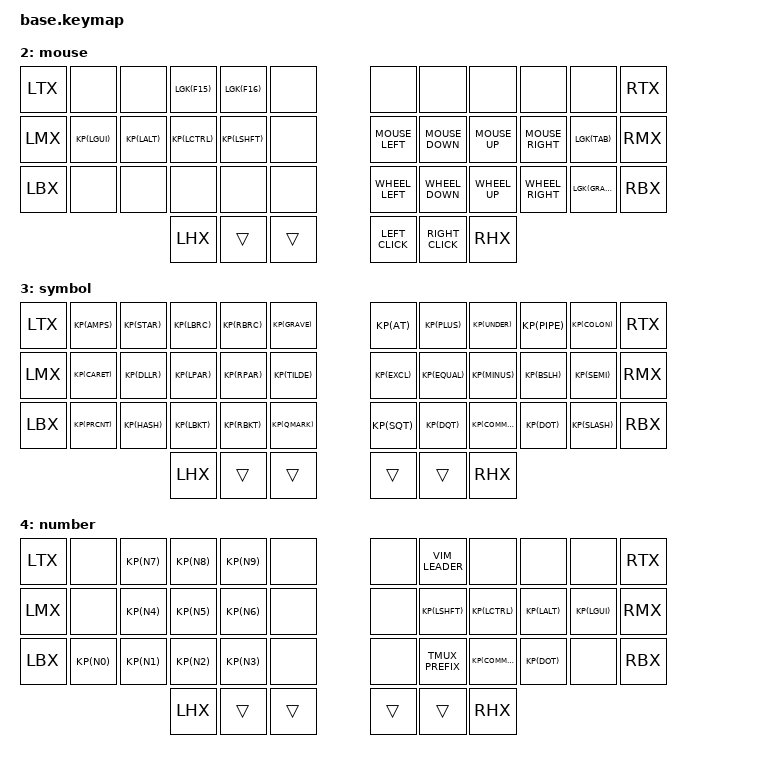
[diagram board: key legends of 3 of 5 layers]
/*
 * Copyright (c) 2020 The ZMK Contributors
 *
 * SPDX-License-Identifier: MIT
 */

// Layers
#define BASE 0
#define NAV 1
#define MOU 2
#define SYM 3
#define NUM 4

// Keys
#define KEYS_L LT0 LT1 LT2 LT3 LT4 LM0 LM1 LM2 LM3 LM4 LB0 LB1 LB2 LB3 LB4
#define KEYS_R RT0 RT1 RT2 RT3 RT4 RM0 RM1 RM2 RM3 RM4 RB0 RB1 RB2 RB3 RB4
#define THUMBS LH1 LH0 RH0 RH1

// Keymaps
#define XXX &none
#define ___ &trans
#define KP(k) &kp k
#define LGK(k) &kp LG(k)
#define LSK(k) &kp LS(k)
#define LCK(k) &kp LC(k)
#define HYPER(k) &kp LC(LS(LA(LG(k))))

#define NAV_ESC &lt NAV ESC
#define MOU_SPACE &lt MOU SPACE
#define NUM_ENTER &lt NUM ENTER
#define SYM_BSPC &lt SYM BSPC

#define BRI_DOWN &kp C_BRI_DN
#define BRI_UP &kp C_BRI_UP

#define VOL_UP &kp C_VOL_UP
#define VOL_DOWN &kp C_VOL_DN
#define VOL_MUTE &kp C_MUTE

#define TMUX_PREFIX LCK(F)
#define VIM_LEADER KP(SEMI)

#include <behaviors.dtsi>
#include <dt-bindings/zmk/bt.h>
#include <dt-bindings/zmk/keys.h>

#include "zmk-helpers/helper.h"

#include "includes/mouse.dtsi"
#include "includes/macros.dtsi"
#include "includes/combos.dtsi"
#include "includes/mods.dtsi"
#include "includes/swapper.dtsi"
#include "includes/settings.dtsi"

ZMK_LAYER(base,
  //╭──────────┬──────────┬──────────┬──────────┬──────────┬──────────╮   ╭──────────┬──────────┬──────────┬──────────┬──────────┬──────────╮
  //│          │  Q       │  W       │  E       │  R       │  T       │   │  Y       │  U       │  I       │  O       │  P       │          │
      _LTX       KP(Q)      KP(W)      KP(E)      KP(R)      KP(T)          KP(Y)      KP(U)      KP(I)      KP(O)      KP(P)      _RTX
  //├──────────┼──────────┼──────────┼──────────┼──────────┼──────────┤   ├──────────┼──────────┼──────────┼──────────┼──────────┼──────────┤
  //│          │  A       │  S       │  D       │  F       │  G       │   │  H       │  J       │  K       │  L       │  ; :     │          │
      _LMX       HRML(A,         S,         D,         F,         G)        HRMR(H,         J,         K,         L,        SEMI)  _RMX
  //├──────────┼──────────┼──────────┼──────────┼──────────┼──────────┤   ├──────────┼──────────┼──────────┼──────────┼──────────┼──────────┤
  //│          │  Z       │  X       │  C       │  V       │  B       │   │  N       │  M       │  , <     │  . >     │  / ?     │          │
      _LBX       KP(Z)      KP(X)      KP(C)      KP(V)      KP(B)          KP(N)      KP(M)      KP(COMMA)  KP(DOT)    KP(SLASH)  _RBX
  //╰──────────┴──────────┴──────────┼──────────┼──────────┼──────────┤   ├──────────┼──────────┼──────────┼──────────┴──────────┴──────────╯
                                       _LHX       NAV_ESC    MOU_SPACE      NUM_ENTER  SYM_BSPC   _RHX
  //                                 ╰──────────┴──────────┴──────────╯   ╰──────────┴──────────┴──────────╯
)

ZMK_LAYER(navigation,
  //╭──────────┬──────────┬──────────┬──────────┬──────────┬──────────╮   ╭──────────┬──────────┬──────────┬──────────┬──────────┬──────────╮
  //│          │          │          │Screenshot│          │          │   │          │          │          │          │ CS + Tab │          │
      _LTX       BRI_DOWN   BRI_UP     HYPER(N4)  XXX        XXX            XXX        XXX        XXX        XXX       KP(LS(TAB)) _RTX
  //├──────────┼──────────┼──────────┼──────────┼──────────┼──────────┤   ├──────────┼──────────┼──────────┼──────────┼──────────┼──────────┤
  //│          │  Command │  Alt     │  Control │  Shift   │          │   │  Left    │  Down    │  Up      │  Right   │ Cmd + Tab│          │
      _LMX       KP(LGUI)   KP(LALT)   KP(LCTRL)  KP(LSHFT)  XXX            KP(LEFT)   KP(DOWN)   KP(UP)     KP(RIGHT)  &swapper   _RMX
  //├──────────┼──────────┼──────────┼──────────┼──────────┼──────────┤   ├──────────┼──────────┼──────────┼──────────┼──────────┼──────────┤
  //│          │ Vol down │ Vol up   │ Vol mute │Tmux Pre  │          │   │ Nav left │ Vim left │ Vim right│ Nav right│ Cmd + `  │          │
      _LBX       VOL_DOWN   VOL_UP     VOL_MUTE TMUX_PREFIX  XXX            KP(F23)    LSK(LEFT)  LSK(RIGHT) KP(F24)   LGK(GRAVE)  _RBX
  //╰──────────┴──────────┴──────────┼──────────┼──────────┼──────────┤   ├──────────┼──────────┼──────────┼──────────┴──────────┴──────────╯
                                       _LHX       ___        ___            ___        ___        _RHX
  //                                 ╰──────────┴──────────┴──────────╯   ╰──────────┴──────────┴──────────╯
)

ZMK_LAYER(mouse,
  //╭──────────┬──────────┬──────────┬──────────┬──────────┬──────────╮   ╭──────────┬──────────┬──────────┬──────────┬──────────┬──────────╮
  //│          │          │          │ Low speed│ Max speed│          │   │          │          │          │          │          │          │
      _LTX       XXX        XXX        LGK(F15)   LGK(F16)   XXX            XXX        XXX        XXX         XXX       XXX        _RTX
  //├──────────┼──────────┼──────────┼──────────┼──────────┼──────────┤   ├──────────┼──────────┼──────────┼──────────┼──────────┼──────────┤
  //│          │ Command  │ Alt      │ Control  │ Shift    │          │   │          │          │          │          │ Cmd + Tab│          │
      _LMX       KP(LGUI)   KP(LALT)   KP(LCTRL)  KP(LSHFT)  XXX           MOUSE_LEFT MOUSE_DOWN  MOUSE_UP  MOUSE_RIGHT LGK(TAB)  _RMX
  //├──────────┼──────────┼──────────┼──────────┼──────────┼──────────┤   ├──────────┼──────────┼──────────┼──────────┼──────────┼──────────┤
  //│          │          │          │          │          │          │   │          │          │          │          │ Cmd + `  │          │
      _LBX       XXX        XXX        XXX        XXX        XXX           WHEEL_LEFT WHEEL_DOWN  WHEEL_UP  WHEEL_RIGHT LGK(GRAVE)  _RBX
  //╰──────────┴──────────┴──────────┼──────────┼──────────┼──────────┤   ├──────────┼──────────┼──────────┼──────────┴──────────┴──────────╯
                                       _LHX       ___        ___           LEFT_CLICK RIGHT_CLICK _RHX
  //                                 ╰──────────┴──────────┴──────────╯   ╰──────────┴──────────┴──────────╯
)

ZMK_LAYER(symbol,
  //╭──────────┬──────────┬──────────┬──────────┬──────────┬──────────╮   ╭──────────┬──────────┬──────────┬──────────┬──────────┬──────────╮
  //│          │  &       │  *       │  {       │  }       │  `       │   │  @       │  +       │  _       │  |       │  :       │          │
      _LTX       KP(AMPS)   KP(STAR)   KP(LBRC)   KP(RBRC)   KP(GRAVE)      KP(AT)     KP(PLUS)   KP(UNDER)  KP(PIPE)   KP(COLON)  _RTX
  //├──────────┼──────────┼──────────┼──────────┼──────────┼──────────┤   ├──────────┼──────────┼──────────┼──────────┼──────────┼──────────┤
  //│          │  ^       │  $       │  (       │  )       │  ~       │   │  !       │  =       │  -       │  \       │  ;       │          │
      _LMX       KP(CARET)  KP(DLLR)   KP(LPAR)   KP(RPAR)   KP(TILDE)      KP(EXCL)   KP(EQUAL)  KP(MINUS)  KP(BSLH)   KP(SEMI)   _RMX
  //├──────────┼──────────┼──────────┼──────────┼──────────┼──────────┤   ├──────────┼──────────┼──────────┼──────────┼──────────┼──────────┤
  //│          │  %       │  #       │  [       │  ]       │  ?       │   │  '       │  "       │  ,       │  .       │  /       │          │
      _LBX       KP(PRCNT)  KP(HASH)   KP(LBKT)   KP(RBKT)   KP(QMARK)      KP(SQT)    KP(DQT)    KP(COMMA)  KP(DOT)    KP(SLASH)  _RBX
  //╰──────────┴──────────┴──────────┼──────────┼──────────┼──────────┤   ├──────────┼──────────┼──────────┼──────────┴──────────┴──────────╯
                                       _LHX       ___        ___            ___        ___        _RHX
  //                                 ╰──────────┴──────────┴──────────╯   ╰──────────┴──────────┴──────────╯
)

ZMK_LAYER(number,
  //╭──────────┬──────────┬──────────┬──────────┬──────────┬──────────╮   ╭──────────┬──────────┬──────────┬──────────┬──────────┬──────────╮
  //│          │          │  7       │  8       │  9       │          │   │          │Vim leader│          │          │          │          │
      _LTX       XXX        KP(N7)     KP(N8)     KP(N9)     XXX            XXX       VIM_LEADER  XXX        XXX        XXX        _RTX
  //├──────────┼──────────┼──────────┼──────────┼──────────┼──────────┤   ├──────────┼──────────┼──────────┼──────────┼──────────┼──────────┤
  //│          │          │  4       │  5       │  6       │          │   │          │  Shift   │  Control │  Alt     │  Command │          │
      _LMX       XXX        KP(N4)     KP(N5)     KP(N6)     XXX            XXX        KP(LSHFT)  KP(LCTRL)  KP(LALT)   KP(LGUI)   _RMX
  //├──────────┼──────────┼──────────┼──────────┼──────────┼──────────┤   ├──────────┼──────────┼──────────┼──────────┼──────────┼──────────┤
  //│          │  0       │  1       │  2       │  3       │          │   │          │Tmux pre  │  ,       │  .       │          │          │
      _LBX       KP(N0)     KP(N1)     KP(N2)     KP(N3)     XXX            XXX      TMUX_PREFIX  KP(COMMA)  KP(DOT)    XXX        _RBX
  //╰──────────┴──────────┴──────────┼──────────┼──────────┼──────────┤   ├──────────┼──────────┼──────────┼──────────┴──────────┴──────────╯
                                       _LHX       ___        ___            ___        ___        _RHX
  //                                 ╰──────────┴──────────┴──────────╯   ╰──────────┴──────────┴──────────╯
)
